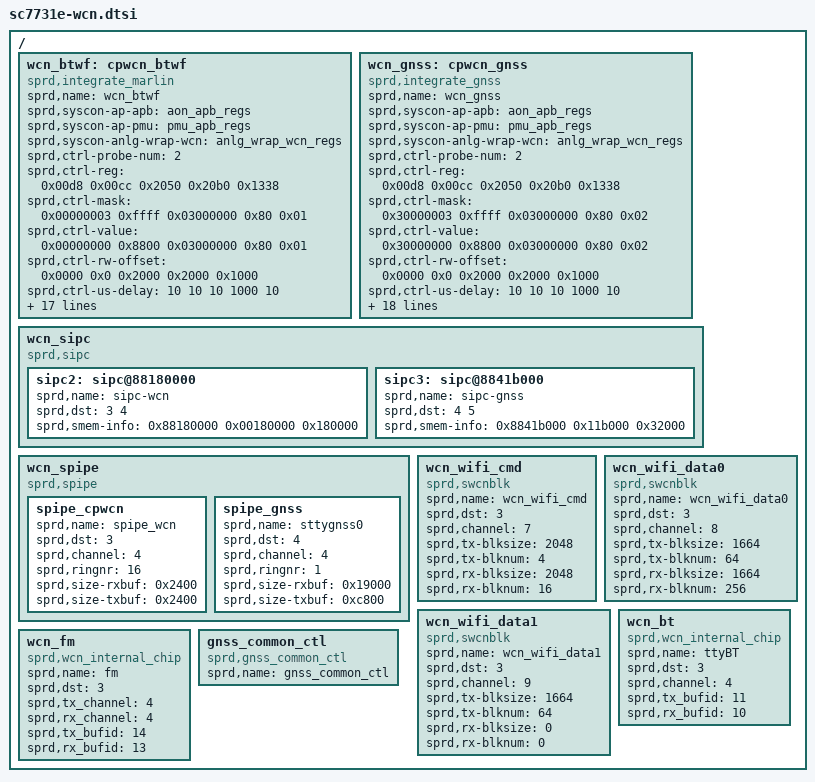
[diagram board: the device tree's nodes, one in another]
/*
 * Spreadtrum SC7731E wcn board DTSI file
 * These dt is used for modem drivers
 *
 * Copyright (C) 2017, Spreadtrum Communications Inc.
 *
 * This file is licensed under a dual GPLv2 or X11 license.
 */

/ {
	wcn_btwf: cpwcn_btwf {    /* <WCN_BTWF_START_ADDR> */
		compatible = "sprd,integrate_marlin";
		sprd,name = "wcn_btwf";
		sprd,syscon-ap-apb = <&aon_apb_regs>;
		sprd,syscon-ap-pmu = <&pmu_apb_regs>;
		sprd,syscon-anlg-wrap-wcn = <&anlg_wrap_wcn_regs>;
		/* Boot Up group:
		 * <BootSequencem,Remap addr,PowerOn,
		 * Reset/ResetRelease,Wcn_sys_en>
		 */
		sprd,ctrl-probe-num = <2>;
		sprd,ctrl-reg = <0x00d8 0x00cc 0x2050 0x20b0 0x1338>;
		sprd,ctrl-mask = <0x00000003 0xffff 0x03000000
				  0x80 0x01>;
		sprd,ctrl-value = <0x00000000 0x8800 0x03000000
				  0x80 0x01>;
		sprd,ctrl-rw-offset = <0x0000 0x0 0x2000 0x2000 0x1000>;
		sprd,ctrl-us-delay = <10 10 10 1000 10>;
		sprd,ctrl-type = <0x0 0x0 0x1 0x1 0x1>;
		/* Add shutdown group:WCN_Disable */
		sprd,ctrl-shutdown-reg = <0x2338>;
		sprd,ctrl-shutdown-mask = <0x01>;
		sprd,ctrl-shutdown-value = <0x01>;
		sprd,ctrl-shutdown-rw-offset = <0x2000>;
		sprd,ctrl-shutdown-us-delay = <10>;
		sprd,ctrl-shutdown-type = <0x1>;
		reg = <0x88000000 0x180000>;
		sprd,file-name = "/dev/block/platform/soc/soc:ap-ahb/20600000.sdio/by-name/wcnmodem";
		sprd,file-length=<0x178000>;
		memory_region = < &wcn_reserved >;
		vddwcn-supply = <&vddcon>;
		vddwifipa-supply = <&vddwifipa>;
		#address-cells = <1>;
		#size-cells = <1>;
		nvmem-cells = <&wcn_alpha>, <&wcn_beta>, <&wcn_gamma>;
		nvmem-cell-names = "wcn_efuse_blk0", "wcn_efuse_blk1",
				   "wcn_efuse_blk2";
	};

	wcn_gnss: cpwcn_gnss {    /* <WCN_GNSS_START_ADDR> */
		compatible = "sprd,integrate_gnss";
		sprd,name = "wcn_gnss";
		sprd,syscon-ap-apb = <&aon_apb_regs>;
		sprd,syscon-ap-pmu = <&pmu_apb_regs>;
		sprd,syscon-anlg-wrap-wcn = <&anlg_wrap_wcn_regs>;
		sprd,ctrl-probe-num = <2>;
		sprd,ctrl-reg = <0x00d8 0x00cc 0x2050 0x20b0
				0x1338>;
		sprd,ctrl-mask = <0x30000003 0xffff 0x03000000
				   0x80 0x02>;
		sprd,ctrl-value = <0x30000000 0x8800 0x03000000
				   0x80 0x02>;
		sprd,ctrl-rw-offset = <0x0000 0x0 0x2000 0x2000
				0x1000>;
		sprd,ctrl-us-delay = <10 10 10 1000 10>;
		sprd,ctrl-type = <0x0 0x0 0x1 0x1 0x1>;
		/* Add shutdown group:WCN_Disable */
		sprd,ctrl-shutdown-reg = <0x2338>;
		sprd,ctrl-shutdown-mask = <0x02>;
		sprd,ctrl-shutdown-value = <0x02>;
		sprd,ctrl-shutdown-rw-offset = <0x2000>;
		sprd,ctrl-shutdown-us-delay = <10>;
		sprd,ctrl-shutdown-type = <0x1>;
		reg = <0x88300000 0x100000>;
		sprd,file-name = "/dev/block/platform/soc/soc:ap-ahb/20600000.sdio/by-name/gpsgl";
		sprd,file-name-ext = "/dev/block/platform/soc/soc:ap-ahb/20600000.sdio/by-name/gpsbd";
		sprd,file-length=<0x100000>;    /* The CP BIN file length */
		memory_region = < &gnss_reserved >;
		vddwcn-supply = <&vddcon>;
		#address-cells = <1>;
		#size-cells = <1>;
		nvmem-cells = <&wcn_delta>, <&wcn_beta>, <&wcn_gamma>;
		nvmem-cell-names = "gnss_efuse_blk0", "gnss_efuse_blk1",
				   "gnss_efuse_blk2";
	};

	wcn_sipc {
		compatible = "sprd,sipc";
		sipc2: sipc@88180000 {
			sprd,name = "sipc-wcn";
			sprd,dst = <3 4>; /* <dst core-id> */
			/* <ap-addr dst-maped-addr size> */
			sprd,smem-info = <0x88180000 0x00180000 0x180000>;
		};

		sipc3: sipc@8841b000 {
			sprd,name = "sipc-gnss";
			sprd,dst = <4 5>; /* <dst core-id> */
			/* <ap-addr dst-maped-addr size> */
			sprd,smem-info = <0x8841b000 0x11b000 0x32000>;
		};
	};

	wcn_spipe {
		compatible = "sprd,spipe";
		spipe_cpwcn {
			sprd,name = "spipe_wcn";
			sprd,dst = <3>;
			sprd,channel = <4>;
			sprd,ringnr = <16>; /* bufid=5:ATCMD, */
			sprd,size-rxbuf = <0x2400>; /* 9 * 1024 */
			sprd,size-txbuf = <0x2400>; /* 9 * 1024 */
		};

		spipe_gnss {
			sprd,name = "sttygnss0";
			sprd,dst = <4>;
			sprd,channel = <4>;
			sprd,ringnr = <1>;
			sprd,size-rxbuf = <0x19000>; /* 100*1024 */
			sprd,size-txbuf = <0xc800>; /* 50*1024 */
		};
	};

	wcn_wifi_cmd {
		compatible = "sprd,swcnblk";
		sprd,name = "wcn_wifi_cmd";
		sprd,dst = <3>;
		sprd,channel = <7>;
		sprd,tx-blksize = <2048>;
		sprd,tx-blknum = <4>;
		sprd,rx-blksize = <2048>;
		sprd,rx-blknum = <16>;
	};

	wcn_wifi_data0 {
		compatible = "sprd,swcnblk";
		sprd,name = "wcn_wifi_data0";
		sprd,dst = <3>;
		sprd,channel = <8>;
		sprd,tx-blksize = <1664>;
		sprd,tx-blknum = <64>;
		sprd,rx-blksize = <1664>;
		sprd,rx-blknum = <256>;
	};

	wcn_wifi_data1 {
		compatible = "sprd,swcnblk";
		sprd,name = "wcn_wifi_data1";
		sprd,dst = <3>;
		sprd,channel = <9>;
		sprd,tx-blksize = <1664>;
		sprd,tx-blknum = <64>;
		sprd,rx-blksize = <0>;
		sprd,rx-blknum = <0>;
	};

	wcn_bt {
		compatible = "sprd,wcn_internal_chip";
		sprd,name = "ttyBT";
		sprd,dst = <3>;
		sprd,channel = <4>;
		sprd,tx_bufid = <11>;
		sprd,rx_bufid = <10>;
	};

	wcn_fm {
		compatible = "sprd,wcn_internal_chip";
		sprd,name = "fm";
		sprd,dst = <3>;
		sprd,tx_channel = <4>;
		sprd,rx_channel = <4>;
		sprd,tx_bufid = <14>;
		sprd,rx_bufid = <13>;
	};

	gnss_common_ctl {
		compatible = "sprd,gnss_common_ctl";
		sprd,name = "gnss_common_ctl";
	};
};
